# YTM32B1HA0 register map
Vendor: YTMicro; File version: 1.0
CPU: little endian, MPU, FPU, 2 interrupt priority bits
Registers are 32-bit, read-write, reset 0x0 unless marked. A register's access mark holds for its fields unless they carry their own. Offsets are from the block's base; [hi:lo] are bit positions; {n}, {i} and the like mark numbered series; 'fields as' and 'values as' point back to an identical list.

## CAN0 (part 4 of 5) — FlexCAN module
Base 0x400D0000; register names take the prefix CAN0_
0x918 RXIMR38 — The RX Individual Mask Registers are used to store the acceptance masks for ID filtering in Rx MBs and the Legacy Rx FIFO. When the Legacy Rx FIFO is disabled (CAN_MCR.RFEN is negated), an individual mask is provided for each available Rx mailbox on a one-to-one correspondence. When the Legacy Rx FIFO is enabled (CAN_MCR.RFEN is asserted), an individual mask is provided for each Legacy Rx FIFO ID Filter Table Element on a one-to-one correspondence depending on the setting of $ ewline$ CAN_CTRL2.RFFN (see \hyperref[legacy-rx-fifo]{"Legacy Rx FIFO"}). CAN_RXIMR0 stores the individual mask associated with either MB0 or ID Filter Table Element 0, CAN_RXIMR1 stores the individual mask associated with either MB1 or ID Filter Table Element 1, and so on. CAN_RXIMRn registers can only be accessed by the CPU when the FlexCAN is in Freeze mode; otherwise, they are blocked by hardware. The CAN_RXIMRn registers are not affected by reset. They are located in RAM and must be explicitly initialized prior to any reception. The CAN_RXIMRn registers are not available if parameter IRMQ_EN is 0.
  [31:0] MI — Each Individual Mask Bit masks the corresponding bit in both the mailbox filter and Legacy Rx FIFO ID Filter Table element in distinct ways. For mailbox filters, see the RXMGMASK register description. For Legacy Rx FIFO ID Filter Table elements, see the RXFGMASK register description. 0b - The corresponding bit in the filter is ``don't care". 1b - The corresponding bit in the filter is checked.
0x91C RXIMR39 — The RX Individual Mask Registers are used to store the acceptance masks for ID filtering in Rx MBs and the Legacy Rx FIFO. When the Legacy Rx FIFO is disabled (CAN_MCR.RFEN is negated), an individual mask is provided for each available Rx mailbox on a one-to-one correspondence. When the Legacy Rx FIFO is enabled (CAN_MCR.RFEN is asserted), an individual mask is provided for each Legacy Rx FIFO ID Filter Table Element on a one-to-one correspondence depending on the setting of $ ewline$ CAN_CTRL2.RFFN (see \hyperref[legacy-rx-fifo]{"Legacy Rx FIFO"}). CAN_RXIMR0 stores the individual mask associated with either MB0 or ID Filter Table Element 0, CAN_RXIMR1 stores the individual mask associated with either MB1 or ID Filter Table Element 1, and so on. CAN_RXIMRn registers can only be accessed by the CPU when the FlexCAN is in Freeze mode; otherwise, they are blocked by hardware. The CAN_RXIMRn registers are not affected by reset. They are located in RAM and must be explicitly initialized prior to any reception. The CAN_RXIMRn registers are not available if parameter IRMQ_EN is 0.
  fields as RXIMR38
0x920 RXIMR40 — The RX Individual Mask Registers are used to store the acceptance masks for ID filtering in Rx MBs and the Legacy Rx FIFO. When the Legacy Rx FIFO is disabled (CAN_MCR.RFEN is negated), an individual mask is provided for each available Rx mailbox on a one-to-one correspondence. When the Legacy Rx FIFO is enabled (CAN_MCR.RFEN is asserted), an individual mask is provided for each Legacy Rx FIFO ID Filter Table Element on a one-to-one correspondence depending on the setting of $ ewline$ CAN_CTRL2.RFFN (see \hyperref[legacy-rx-fifo]{"Legacy Rx FIFO"}). CAN_RXIMR0 stores the individual mask associated with either MB0 or ID Filter Table Element 0, CAN_RXIMR1 stores the individual mask associated with either MB1 or ID Filter Table Element 1, and so on. CAN_RXIMRn registers can only be accessed by the CPU when the FlexCAN is in Freeze mode; otherwise, they are blocked by hardware. The CAN_RXIMRn registers are not affected by reset. They are located in RAM and must be explicitly initialized prior to any reception. The CAN_RXIMRn registers are not available if parameter IRMQ_EN is 0.
  fields as RXIMR38
0x924 RXIMR41 — The RX Individual Mask Registers are used to store the acceptance masks for ID filtering in Rx MBs and the Legacy Rx FIFO. When the Legacy Rx FIFO is disabled (CAN_MCR.RFEN is negated), an individual mask is provided for each available Rx mailbox on a one-to-one correspondence. When the Legacy Rx FIFO is enabled (CAN_MCR.RFEN is asserted), an individual mask is provided for each Legacy Rx FIFO ID Filter Table Element on a one-to-one correspondence depending on the setting of $ ewline$ CAN_CTRL2.RFFN (see \hyperref[legacy-rx-fifo]{"Legacy Rx FIFO"}). CAN_RXIMR0 stores the individual mask associated with either MB0 or ID Filter Table Element 0, CAN_RXIMR1 stores the individual mask associated with either MB1 or ID Filter Table Element 1, and so on. CAN_RXIMRn registers can only be accessed by the CPU when the FlexCAN is in Freeze mode; otherwise, they are blocked by hardware. The CAN_RXIMRn registers are not affected by reset. They are located in RAM and must be explicitly initialized prior to any reception. The CAN_RXIMRn registers are not available if parameter IRMQ_EN is 0.
  fields as RXIMR38
0x928 RXIMR42 — The RX Individual Mask Registers are used to store the acceptance masks for ID filtering in Rx MBs and the Legacy Rx FIFO. When the Legacy Rx FIFO is disabled (CAN_MCR.RFEN is negated), an individual mask is provided for each available Rx mailbox on a one-to-one correspondence. When the Legacy Rx FIFO is enabled (CAN_MCR.RFEN is asserted), an individual mask is provided for each Legacy Rx FIFO ID Filter Table Element on a one-to-one correspondence depending on the setting of $ ewline$ CAN_CTRL2.RFFN (see \hyperref[legacy-rx-fifo]{"Legacy Rx FIFO"}). CAN_RXIMR0 stores the individual mask associated with either MB0 or ID Filter Table Element 0, CAN_RXIMR1 stores the individual mask associated with either MB1 or ID Filter Table Element 1, and so on. CAN_RXIMRn registers can only be accessed by the CPU when the FlexCAN is in Freeze mode; otherwise, they are blocked by hardware. The CAN_RXIMRn registers are not affected by reset. They are located in RAM and must be explicitly initialized prior to any reception. The CAN_RXIMRn registers are not available if parameter IRMQ_EN is 0.
  fields as RXIMR38
0x92C RXIMR43 — The RX Individual Mask Registers are used to store the acceptance masks for ID filtering in Rx MBs and the Legacy Rx FIFO. When the Legacy Rx FIFO is disabled (CAN_MCR.RFEN is negated), an individual mask is provided for each available Rx mailbox on a one-to-one correspondence. When the Legacy Rx FIFO is enabled (CAN_MCR.RFEN is asserted), an individual mask is provided for each Legacy Rx FIFO ID Filter Table Element on a one-to-one correspondence depending on the setting of $ ewline$ CAN_CTRL2.RFFN (see \hyperref[legacy-rx-fifo]{"Legacy Rx FIFO"}). CAN_RXIMR0 stores the individual mask associated with either MB0 or ID Filter Table Element 0, CAN_RXIMR1 stores the individual mask associated with either MB1 or ID Filter Table Element 1, and so on. CAN_RXIMRn registers can only be accessed by the CPU when the FlexCAN is in Freeze mode; otherwise, they are blocked by hardware. The CAN_RXIMRn registers are not affected by reset. They are located in RAM and must be explicitly initialized prior to any reception. The CAN_RXIMRn registers are not available if parameter IRMQ_EN is 0.
  fields as RXIMR38
0x930 RXIMR44 — The RX Individual Mask Registers are used to store the acceptance masks for ID filtering in Rx MBs and the Legacy Rx FIFO. When the Legacy Rx FIFO is disabled (CAN_MCR.RFEN is negated), an individual mask is provided for each available Rx mailbox on a one-to-one correspondence. When the Legacy Rx FIFO is enabled (CAN_MCR.RFEN is asserted), an individual mask is provided for each Legacy Rx FIFO ID Filter Table Element on a one-to-one correspondence depending on the setting of $ ewline$ CAN_CTRL2.RFFN (see \hyperref[legacy-rx-fifo]{"Legacy Rx FIFO"}). CAN_RXIMR0 stores the individual mask associated with either MB0 or ID Filter Table Element 0, CAN_RXIMR1 stores the individual mask associated with either MB1 or ID Filter Table Element 1, and so on. CAN_RXIMRn registers can only be accessed by the CPU when the FlexCAN is in Freeze mode; otherwise, they are blocked by hardware. The CAN_RXIMRn registers are not affected by reset. They are located in RAM and must be explicitly initialized prior to any reception. The CAN_RXIMRn registers are not available if parameter IRMQ_EN is 0.
  fields as RXIMR38
0x934 RXIMR45 — The RX Individual Mask Registers are used to store the acceptance masks for ID filtering in Rx MBs and the Legacy Rx FIFO. When the Legacy Rx FIFO is disabled (CAN_MCR.RFEN is negated), an individual mask is provided for each available Rx mailbox on a one-to-one correspondence. When the Legacy Rx FIFO is enabled (CAN_MCR.RFEN is asserted), an individual mask is provided for each Legacy Rx FIFO ID Filter Table Element on a one-to-one correspondence depending on the setting of $ ewline$ CAN_CTRL2.RFFN (see \hyperref[legacy-rx-fifo]{"Legacy Rx FIFO"}). CAN_RXIMR0 stores the individual mask associated with either MB0 or ID Filter Table Element 0, CAN_RXIMR1 stores the individual mask associated with either MB1 or ID Filter Table Element 1, and so on. CAN_RXIMRn registers can only be accessed by the CPU when the FlexCAN is in Freeze mode; otherwise, they are blocked by hardware. The CAN_RXIMRn registers are not affected by reset. They are located in RAM and must be explicitly initialized prior to any reception. The CAN_RXIMRn registers are not available if parameter IRMQ_EN is 0.
  fields as RXIMR38
0x938 RXIMR46 — The RX Individual Mask Registers are used to store the acceptance masks for ID filtering in Rx MBs and the Legacy Rx FIFO. When the Legacy Rx FIFO is disabled (CAN_MCR.RFEN is negated), an individual mask is provided for each available Rx mailbox on a one-to-one correspondence. When the Legacy Rx FIFO is enabled (CAN_MCR.RFEN is asserted), an individual mask is provided for each Legacy Rx FIFO ID Filter Table Element on a one-to-one correspondence depending on the setting of $ ewline$ CAN_CTRL2.RFFN (see \hyperref[legacy-rx-fifo]{"Legacy Rx FIFO"}). CAN_RXIMR0 stores the individual mask associated with either MB0 or ID Filter Table Element 0, CAN_RXIMR1 stores the individual mask associated with either MB1 or ID Filter Table Element 1, and so on. CAN_RXIMRn registers can only be accessed by the CPU when the FlexCAN is in Freeze mode; otherwise, they are blocked by hardware. The CAN_RXIMRn registers are not affected by reset. They are located in RAM and must be explicitly initialized prior to any reception. The CAN_RXIMRn registers are not available if parameter IRMQ_EN is 0.
  fields as RXIMR38
0x93C RXIMR47 — The RX Individual Mask Registers are used to store the acceptance masks for ID filtering in Rx MBs and the Legacy Rx FIFO. When the Legacy Rx FIFO is disabled (CAN_MCR.RFEN is negated), an individual mask is provided for each available Rx mailbox on a one-to-one correspondence. When the Legacy Rx FIFO is enabled (CAN_MCR.RFEN is asserted), an individual mask is provided for each Legacy Rx FIFO ID Filter Table Element on a one-to-one correspondence depending on the setting of $ ewline$ CAN_CTRL2.RFFN (see \hyperref[legacy-rx-fifo]{"Legacy Rx FIFO"}). CAN_RXIMR0 stores the individual mask associated with either MB0 or ID Filter Table Element 0, CAN_RXIMR1 stores the individual mask associated with either MB1 or ID Filter Table Element 1, and so on. CAN_RXIMRn registers can only be accessed by the CPU when the FlexCAN is in Freeze mode; otherwise, they are blocked by hardware. The CAN_RXIMRn registers are not affected by reset. They are located in RAM and must be explicitly initialized prior to any reception. The CAN_RXIMRn registers are not available if parameter IRMQ_EN is 0.
  fields as RXIMR38
0x940 RXIMR48 — The RX Individual Mask Registers are used to store the acceptance masks for ID filtering in Rx MBs and the Legacy Rx FIFO. When the Legacy Rx FIFO is disabled (CAN_MCR.RFEN is negated), an individual mask is provided for each available Rx mailbox on a one-to-one correspondence. When the Legacy Rx FIFO is enabled (CAN_MCR.RFEN is asserted), an individual mask is provided for each Legacy Rx FIFO ID Filter Table Element on a one-to-one correspondence depending on the setting of $ ewline$ CAN_CTRL2.RFFN (see \hyperref[legacy-rx-fifo]{"Legacy Rx FIFO"}). CAN_RXIMR0 stores the individual mask associated with either MB0 or ID Filter Table Element 0, CAN_RXIMR1 stores the individual mask associated with either MB1 or ID Filter Table Element 1, and so on. CAN_RXIMRn registers can only be accessed by the CPU when the FlexCAN is in Freeze mode; otherwise, they are blocked by hardware. The CAN_RXIMRn registers are not affected by reset. They are located in RAM and must be explicitly initialized prior to any reception. The CAN_RXIMRn registers are not available if parameter IRMQ_EN is 0.
  fields as RXIMR38
0x944 RXIMR49 — The RX Individual Mask Registers are used to store the acceptance masks for ID filtering in Rx MBs and the Legacy Rx FIFO. When the Legacy Rx FIFO is disabled (CAN_MCR.RFEN is negated), an individual mask is provided for each available Rx mailbox on a one-to-one correspondence. When the Legacy Rx FIFO is enabled (CAN_MCR.RFEN is asserted), an individual mask is provided for each Legacy Rx FIFO ID Filter Table Element on a one-to-one correspondence depending on the setting of $ ewline$ CAN_CTRL2.RFFN (see \hyperref[legacy-rx-fifo]{"Legacy Rx FIFO"}). CAN_RXIMR0 stores the individual mask associated with either MB0 or ID Filter Table Element 0, CAN_RXIMR1 stores the individual mask associated with either MB1 or ID Filter Table Element 1, and so on. CAN_RXIMRn registers can only be accessed by the CPU when the FlexCAN is in Freeze mode; otherwise, they are blocked by hardware. The CAN_RXIMRn registers are not affected by reset. They are located in RAM and must be explicitly initialized prior to any reception. The CAN_RXIMRn registers are not available if parameter IRMQ_EN is 0.
  fields as RXIMR38
0x948 RXIMR50 — The RX Individual Mask Registers are used to store the acceptance masks for ID filtering in Rx MBs and the Legacy Rx FIFO. When the Legacy Rx FIFO is disabled (CAN_MCR.RFEN is negated), an individual mask is provided for each available Rx mailbox on a one-to-one correspondence. When the Legacy Rx FIFO is enabled (CAN_MCR.RFEN is asserted), an individual mask is provided for each Legacy Rx FIFO ID Filter Table Element on a one-to-one correspondence depending on the setting of $ ewline$ CAN_CTRL2.RFFN (see \hyperref[legacy-rx-fifo]{"Legacy Rx FIFO"}). CAN_RXIMR0 stores the individual mask associated with either MB0 or ID Filter Table Element 0, CAN_RXIMR1 stores the individual mask associated with either MB1 or ID Filter Table Element 1, and so on. CAN_RXIMRn registers can only be accessed by the CPU when the FlexCAN is in Freeze mode; otherwise, they are blocked by hardware. The CAN_RXIMRn registers are not affected by reset. They are located in RAM and must be explicitly initialized prior to any reception. The CAN_RXIMRn registers are not available if parameter IRMQ_EN is 0.
  fields as RXIMR38
0x94C RXIMR51 — The RX Individual Mask Registers are used to store the acceptance masks for ID filtering in Rx MBs and the Legacy Rx FIFO. When the Legacy Rx FIFO is disabled (CAN_MCR.RFEN is negated), an individual mask is provided for each available Rx mailbox on a one-to-one correspondence. When the Legacy Rx FIFO is enabled (CAN_MCR.RFEN is asserted), an individual mask is provided for each Legacy Rx FIFO ID Filter Table Element on a one-to-one correspondence depending on the setting of $ ewline$ CAN_CTRL2.RFFN (see \hyperref[legacy-rx-fifo]{"Legacy Rx FIFO"}). CAN_RXIMR0 stores the individual mask associated with either MB0 or ID Filter Table Element 0, CAN_RXIMR1 stores the individual mask associated with either MB1 or ID Filter Table Element 1, and so on. CAN_RXIMRn registers can only be accessed by the CPU when the FlexCAN is in Freeze mode; otherwise, they are blocked by hardware. The CAN_RXIMRn registers are not affected by reset. They are located in RAM and must be explicitly initialized prior to any reception. The CAN_RXIMRn registers are not available if parameter IRMQ_EN is 0.
  fields as RXIMR38
0x950 RXIMR52 — The RX Individual Mask Registers are used to store the acceptance masks for ID filtering in Rx MBs and the Legacy Rx FIFO. When the Legacy Rx FIFO is disabled (CAN_MCR.RFEN is negated), an individual mask is provided for each available Rx mailbox on a one-to-one correspondence. When the Legacy Rx FIFO is enabled (CAN_MCR.RFEN is asserted), an individual mask is provided for each Legacy Rx FIFO ID Filter Table Element on a one-to-one correspondence depending on the setting of $ ewline$ CAN_CTRL2.RFFN (see \hyperref[legacy-rx-fifo]{"Legacy Rx FIFO"}). CAN_RXIMR0 stores the individual mask associated with either MB0 or ID Filter Table Element 0, CAN_RXIMR1 stores the individual mask associated with either MB1 or ID Filter Table Element 1, and so on. CAN_RXIMRn registers can only be accessed by the CPU when the FlexCAN is in Freeze mode; otherwise, they are blocked by hardware. The CAN_RXIMRn registers are not affected by reset. They are located in RAM and must be explicitly initialized prior to any reception. The CAN_RXIMRn registers are not available if parameter IRMQ_EN is 0.
  fields as RXIMR38
0x954 RXIMR53 — The RX Individual Mask Registers are used to store the acceptance masks for ID filtering in Rx MBs and the Legacy Rx FIFO. When the Legacy Rx FIFO is disabled (CAN_MCR.RFEN is negated), an individual mask is provided for each available Rx mailbox on a one-to-one correspondence. When the Legacy Rx FIFO is enabled (CAN_MCR.RFEN is asserted), an individual mask is provided for each Legacy Rx FIFO ID Filter Table Element on a one-to-one correspondence depending on the setting of $ ewline$ CAN_CTRL2.RFFN (see \hyperref[legacy-rx-fifo]{"Legacy Rx FIFO"}). CAN_RXIMR0 stores the individual mask associated with either MB0 or ID Filter Table Element 0, CAN_RXIMR1 stores the individual mask associated with either MB1 or ID Filter Table Element 1, and so on. CAN_RXIMRn registers can only be accessed by the CPU when the FlexCAN is in Freeze mode; otherwise, they are blocked by hardware. The CAN_RXIMRn registers are not affected by reset. They are located in RAM and must be explicitly initialized prior to any reception. The CAN_RXIMRn registers are not available if parameter IRMQ_EN is 0.
  fields as RXIMR38
0x958 RXIMR54 — The RX Individual Mask Registers are used to store the acceptance masks for ID filtering in Rx MBs and the Legacy Rx FIFO. When the Legacy Rx FIFO is disabled (CAN_MCR.RFEN is negated), an individual mask is provided for each available Rx mailbox on a one-to-one correspondence. When the Legacy Rx FIFO is enabled (CAN_MCR.RFEN is asserted), an individual mask is provided for each Legacy Rx FIFO ID Filter Table Element on a one-to-one correspondence depending on the setting of $ ewline$ CAN_CTRL2.RFFN (see \hyperref[legacy-rx-fifo]{"Legacy Rx FIFO"}). CAN_RXIMR0 stores the individual mask associated with either MB0 or ID Filter Table Element 0, CAN_RXIMR1 stores the individual mask associated with either MB1 or ID Filter Table Element 1, and so on. CAN_RXIMRn registers can only be accessed by the CPU when the FlexCAN is in Freeze mode; otherwise, they are blocked by hardware. The CAN_RXIMRn registers are not affected by reset. They are located in RAM and must be explicitly initialized prior to any reception. The CAN_RXIMRn registers are not available if parameter IRMQ_EN is 0.
  fields as RXIMR38
0x95C RXIMR55 — The RX Individual Mask Registers are used to store the acceptance masks for ID filtering in Rx MBs and the Legacy Rx FIFO. When the Legacy Rx FIFO is disabled (CAN_MCR.RFEN is negated), an individual mask is provided for each available Rx mailbox on a one-to-one correspondence. When the Legacy Rx FIFO is enabled (CAN_MCR.RFEN is asserted), an individual mask is provided for each Legacy Rx FIFO ID Filter Table Element on a one-to-one correspondence depending on the setting of $ ewline$ CAN_CTRL2.RFFN (see \hyperref[legacy-rx-fifo]{"Legacy Rx FIFO"}). CAN_RXIMR0 stores the individual mask associated with either MB0 or ID Filter Table Element 0, CAN_RXIMR1 stores the individual mask associated with either MB1 or ID Filter Table Element 1, and so on. CAN_RXIMRn registers can only be accessed by the CPU when the FlexCAN is in Freeze mode; otherwise, they are blocked by hardware. The CAN_RXIMRn registers are not affected by reset. They are located in RAM and must be explicitly initialized prior to any reception. The CAN_RXIMRn registers are not available if parameter IRMQ_EN is 0.
  fields as RXIMR38
0x960 RXIMR56 — The RX Individual Mask Registers are used to store the acceptance masks for ID filtering in Rx MBs and the Legacy Rx FIFO. When the Legacy Rx FIFO is disabled (CAN_MCR.RFEN is negated), an individual mask is provided for each available Rx mailbox on a one-to-one correspondence. When the Legacy Rx FIFO is enabled (CAN_MCR.RFEN is asserted), an individual mask is provided for each Legacy Rx FIFO ID Filter Table Element on a one-to-one correspondence depending on the setting of $ ewline$ CAN_CTRL2.RFFN (see \hyperref[legacy-rx-fifo]{"Legacy Rx FIFO"}). CAN_RXIMR0 stores the individual mask associated with either MB0 or ID Filter Table Element 0, CAN_RXIMR1 stores the individual mask associated with either MB1 or ID Filter Table Element 1, and so on. CAN_RXIMRn registers can only be accessed by the CPU when the FlexCAN is in Freeze mode; otherwise, they are blocked by hardware. The CAN_RXIMRn registers are not affected by reset. They are located in RAM and must be explicitly initialized prior to any reception. The CAN_RXIMRn registers are not available if parameter IRMQ_EN is 0.
  fields as RXIMR38
0x964 RXIMR57 — The RX Individual Mask Registers are used to store the acceptance masks for ID filtering in Rx MBs and the Legacy Rx FIFO. When the Legacy Rx FIFO is disabled (CAN_MCR.RFEN is negated), an individual mask is provided for each available Rx mailbox on a one-to-one correspondence. When the Legacy Rx FIFO is enabled (CAN_MCR.RFEN is asserted), an individual mask is provided for each Legacy Rx FIFO ID Filter Table Element on a one-to-one correspondence depending on the setting of $ ewline$ CAN_CTRL2.RFFN (see \hyperref[legacy-rx-fifo]{"Legacy Rx FIFO"}). CAN_RXIMR0 stores the individual mask associated with either MB0 or ID Filter Table Element 0, CAN_RXIMR1 stores the individual mask associated with either MB1 or ID Filter Table Element 1, and so on. CAN_RXIMRn registers can only be accessed by the CPU when the FlexCAN is in Freeze mode; otherwise, they are blocked by hardware. The CAN_RXIMRn registers are not affected by reset. They are located in RAM and must be explicitly initialized prior to any reception. The CAN_RXIMRn registers are not available if parameter IRMQ_EN is 0.
  fields as RXIMR38
0x968 RXIMR58 — The RX Individual Mask Registers are used to store the acceptance masks for ID filtering in Rx MBs and the Legacy Rx FIFO. When the Legacy Rx FIFO is disabled (CAN_MCR.RFEN is negated), an individual mask is provided for each available Rx mailbox on a one-to-one correspondence. When the Legacy Rx FIFO is enabled (CAN_MCR.RFEN is asserted), an individual mask is provided for each Legacy Rx FIFO ID Filter Table Element on a one-to-one correspondence depending on the setting of $ ewline$ CAN_CTRL2.RFFN (see \hyperref[legacy-rx-fifo]{"Legacy Rx FIFO"}). CAN_RXIMR0 stores the individual mask associated with either MB0 or ID Filter Table Element 0, CAN_RXIMR1 stores the individual mask associated with either MB1 or ID Filter Table Element 1, and so on. CAN_RXIMRn registers can only be accessed by the CPU when the FlexCAN is in Freeze mode; otherwise, they are blocked by hardware. The CAN_RXIMRn registers are not affected by reset. They are located in RAM and must be explicitly initialized prior to any reception. The CAN_RXIMRn registers are not available if parameter IRMQ_EN is 0.
  fields as RXIMR38
0x96C RXIMR59 — The RX Individual Mask Registers are used to store the acceptance masks for ID filtering in Rx MBs and the Legacy Rx FIFO. When the Legacy Rx FIFO is disabled (CAN_MCR.RFEN is negated), an individual mask is provided for each available Rx mailbox on a one-to-one correspondence. When the Legacy Rx FIFO is enabled (CAN_MCR.RFEN is asserted), an individual mask is provided for each Legacy Rx FIFO ID Filter Table Element on a one-to-one correspondence depending on the setting of $ ewline$ CAN_CTRL2.RFFN (see \hyperref[legacy-rx-fifo]{"Legacy Rx FIFO"}). CAN_RXIMR0 stores the individual mask associated with either MB0 or ID Filter Table Element 0, CAN_RXIMR1 stores the individual mask associated with either MB1 or ID Filter Table Element 1, and so on. CAN_RXIMRn registers can only be accessed by the CPU when the FlexCAN is in Freeze mode; otherwise, they are blocked by hardware. The CAN_RXIMRn registers are not affected by reset. They are located in RAM and must be explicitly initialized prior to any reception. The CAN_RXIMRn registers are not available if parameter IRMQ_EN is 0.
  fields as RXIMR38
0x970 RXIMR60 — The RX Individual Mask Registers are used to store the acceptance masks for ID filtering in Rx MBs and the Legacy Rx FIFO. When the Legacy Rx FIFO is disabled (CAN_MCR.RFEN is negated), an individual mask is provided for each available Rx mailbox on a one-to-one correspondence. When the Legacy Rx FIFO is enabled (CAN_MCR.RFEN is asserted), an individual mask is provided for each Legacy Rx FIFO ID Filter Table Element on a one-to-one correspondence depending on the setting of $ ewline$ CAN_CTRL2.RFFN (see \hyperref[legacy-rx-fifo]{"Legacy Rx FIFO"}). CAN_RXIMR0 stores the individual mask associated with either MB0 or ID Filter Table Element 0, CAN_RXIMR1 stores the individual mask associated with either MB1 or ID Filter Table Element 1, and so on. CAN_RXIMRn registers can only be accessed by the CPU when the FlexCAN is in Freeze mode; otherwise, they are blocked by hardware. The CAN_RXIMRn registers are not affected by reset. They are located in RAM and must be explicitly initialized prior to any reception. The CAN_RXIMRn registers are not available if parameter IRMQ_EN is 0.
  fields as RXIMR38
0x974 RXIMR61 — The RX Individual Mask Registers are used to store the acceptance masks for ID filtering in Rx MBs and the Legacy Rx FIFO. When the Legacy Rx FIFO is disabled (CAN_MCR.RFEN is negated), an individual mask is provided for each available Rx mailbox on a one-to-one correspondence. When the Legacy Rx FIFO is enabled (CAN_MCR.RFEN is asserted), an individual mask is provided for each Legacy Rx FIFO ID Filter Table Element on a one-to-one correspondence depending on the setting of $ ewline$ CAN_CTRL2.RFFN (see \hyperref[legacy-rx-fifo]{"Legacy Rx FIFO"}). CAN_RXIMR0 stores the individual mask associated with either MB0 or ID Filter Table Element 0, CAN_RXIMR1 stores the individual mask associated with either MB1 or ID Filter Table Element 1, and so on. CAN_RXIMRn registers can only be accessed by the CPU when the FlexCAN is in Freeze mode; otherwise, they are blocked by hardware. The CAN_RXIMRn registers are not affected by reset. They are located in RAM and must be explicitly initialized prior to any reception. The CAN_RXIMRn registers are not available if parameter IRMQ_EN is 0.
  fields as RXIMR38
0x978 RXIMR62 — The RX Individual Mask Registers are used to store the acceptance masks for ID filtering in Rx MBs and the Legacy Rx FIFO. When the Legacy Rx FIFO is disabled (CAN_MCR.RFEN is negated), an individual mask is provided for each available Rx mailbox on a one-to-one correspondence. When the Legacy Rx FIFO is enabled (CAN_MCR.RFEN is asserted), an individual mask is provided for each Legacy Rx FIFO ID Filter Table Element on a one-to-one correspondence depending on the setting of $ ewline$ CAN_CTRL2.RFFN (see \hyperref[legacy-rx-fifo]{"Legacy Rx FIFO"}). CAN_RXIMR0 stores the individual mask associated with either MB0 or ID Filter Table Element 0, CAN_RXIMR1 stores the individual mask associated with either MB1 or ID Filter Table Element 1, and so on. CAN_RXIMRn registers can only be accessed by the CPU when the FlexCAN is in Freeze mode; otherwise, they are blocked by hardware. The CAN_RXIMRn registers are not affected by reset. They are located in RAM and must be explicitly initialized prior to any reception. The CAN_RXIMRn registers are not available if parameter IRMQ_EN is 0.
  fields as RXIMR38
0x97C RXIMR63 — The RX Individual Mask Registers are used to store the acceptance masks for ID filtering in Rx MBs and the Legacy Rx FIFO. When the Legacy Rx FIFO is disabled (CAN_MCR.RFEN is negated), an individual mask is provided for each available Rx mailbox on a one-to-one correspondence. When the Legacy Rx FIFO is enabled (CAN_MCR.RFEN is asserted), an individual mask is provided for each Legacy Rx FIFO ID Filter Table Element on a one-to-one correspondence depending on the setting of $ ewline$ CAN_CTRL2.RFFN (see \hyperref[legacy-rx-fifo]{"Legacy Rx FIFO"}). CAN_RXIMR0 stores the individual mask associated with either MB0 or ID Filter Table Element 0, CAN_RXIMR1 stores the individual mask associated with either MB1 or ID Filter Table Element 1, and so on. CAN_RXIMRn registers can only be accessed by the CPU when the FlexCAN is in Freeze mode; otherwise, they are blocked by hardware. The CAN_RXIMRn registers are not affected by reset. They are located in RAM and must be explicitly initialized prior to any reception. The CAN_RXIMRn registers are not available if parameter IRMQ_EN is 0.
  fields as RXIMR38
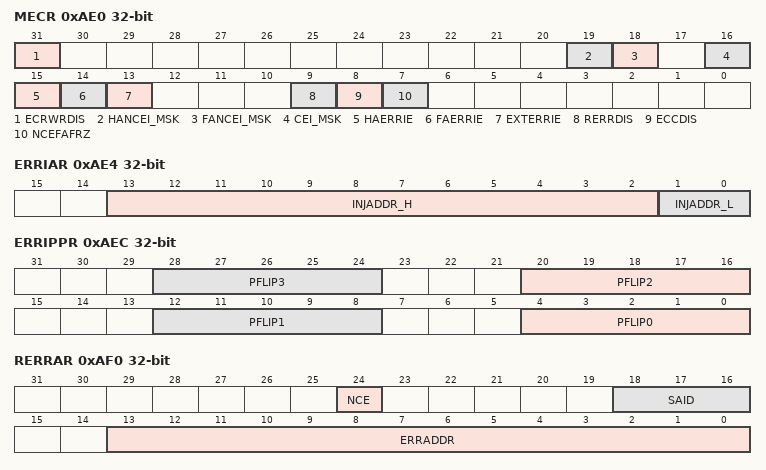
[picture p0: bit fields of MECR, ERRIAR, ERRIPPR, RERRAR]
0xAE0 MECR — The CAN_MECR register contains control bits for memory error detection and correction (ECC). NOTE: When CAN_CTRL2.ECRWRE is 0, writes to CAN_MECR are blocked, with the exception of the ECRWRDIS bit.
  [31] ECRWRDIS — ECRWRDIS is automatically set to 1 (disabled) when CTRL2.ECRWRE is asserted. The protocol described in \hyperref[detection-and-correction-of-memory-errors]{"Detection and Correction of Memory Errors"} must be followed.
    0=Write is enabled; 1=Write is disabled
  [19] HANCEI_MSK — Enables the interrupt in case of non-correctable errors detected in memory reads issued by the host (CPU).
    0=Interrupt is disabled; 1=Interrupt is enabled
  [18] FANCEI_MSK — Enables the interrupt in case of non-correctable errors detected in memory reads issued by the FlexCAN internal processes.
    0=Interrupt is disabled; 1=Interrupt is enabled
  [16] CEI_MSK — Enables the interrupt in case of correctable errors detected in memory reads issued by the host or FlexCAN internal processes.
    0=Interrupt is disabled; 1=Interrupt is enabled
  [15] HAERRIE — Enables the injection of errors only in memory reads issued by the host (CPU).
    0=Interrupt is disabled; 1=Interrupt is enabled
  [14] FAERRIE — Enables the injection of errors only in memory reads issued by the FlexCAN internal processes.
    0=Interrupt is disabled; 1=Interrupt is enabled
  [13] EXTERRIE — Memory accesses performed by internal FlexCAN processes are 64-bit accesses. EXTERRIE extends the error injection on 32-bit memory accesses to the complementary 32-bit word using the same 32-bit error injection data and parity words. See 'Error Injection Data Pattern Register (CAN_ERRIDPR)' and 'Error Injection Parity Pattern Register (CAN_ERRIPPR)'.
    0=Error injection is applied only to the 32-bit word; 1=Error injection is applied to the 64-bit word
  [9] RERRDIS — NOTE: When reading the report registers, RERRDIS must be set to ensure coherence on the consecutive register reads.
    0=Enable updates of the error report registers; 1=Disable updates of the error report registers. The update of error-related flags and the generation of bus transfer errors are still active.
  [8] ECCDIS — In addition to disabling the error report mechanism, ECCDIS = 1 also stops the update of the error-related flags and generation of bus transfer errors. The parity bits continue to be calculated and written into memory on write transactions.
    0=Enable memory error correction; 1=Disable memory error correction
  [7] NCEFAFRZ — Determines the response when a non-correctable error is detected in a memory read performed by FlexCAN internal processes.
    0=Keep normal operation; 1=Put FlexCAN in Freeze mode (according to \hyperref[freeze-mode]{"Freeze Mode"}). In this case, entering Freeze mode prevents corrupted data from being treated as valid by FlexCAN internal processes.
0xAE4 ERRIAR
  [13:2] INJADDR_H — Defines the twelve most significant bits of the physical RAM address where a memory read error is to be injected. See \hyperref[CAN-error-injection-address-mapping-for-maximum-configuration]{CAN error injection address mapping for maximum configuration}
  [1:0] INJADDR_L — Read-only field that defines the two least significant bits of the physical RAM address where a memory read error is to be injected. INJADDR_L[1:0] are always zero to ensure that the address is on a 32-bit boundary.
0xAE8 ERRIDPR — The CAN_ERRIDPR register holds the error pattern to be injected in the data word read from memory. The CAN_ERRIDPR register is not available when parameter ECC_EN is 0.
  [31:0] DFLIP — Bits set to 1 in the flip pattern cause the corresponding data bit in the word read from memory to invert.
0xAEC ERRIPPR — The CAN_ERRIPPR register holds the error pattern to be injected in parity bits read from memory along with data word. Bits set to 1 in the flip pattern cause the corresponding parity bit in the word read from memory to invert. The CAN_ERRIPPR register is not available when parameter ECC_EN is 0.
  [8n+4:8n] PFLIP{n} (n=0..3)
0xAF0 RERRAR — The CAN_RERRAR register reports the address used for an access in which an error (correctable or non-correctable) was detected, and reports the identification of the source of that access. The address is always reported using a 32-bit alignment. Non-aligned accesses ewline (CAN_ERRADDR[1:0] are non-0) are reported with the address aligned and data is reported in CAN_RERRDR accordingly shifted. In case of errors detected in accesses larger than 32-bit (as performed by FlexCAN internal processes), the address of the 32-bit word in which the error was detected is reported. In case of errors detected in more than one 32-bit word, only the least significant address is reported. The CAN_RERRAR register is not available when parameter ECC_EN is 0.
  [24] NCE ro — Indicates that the report is due to a noncorrectable error.
    0=Reporting a correctable-error; 1=Reporting a non-correctable error
  [18:16] SAID ro — SAID[2] - Identification of the requestor of the memory read request: • 0: Requested by FlexCAN internal processes • 1: Requested by host (CPU) SAID[1] - Details of FlexCAN operation: • 0: Move • 1: Scanning SAID[0] - Operation that requested the memory read: • 0: Transmission • 1: Reception
  [13:0] ERRADDR ro

## CAN1 (part 4 of 5) — FlexCAN module
Base 0x400D4000; register names take the prefix CAN1_
Registers as CAN0.

## CAN2 (part 4 of 5) — FlexCAN module
Base 0x400D8000; register names take the prefix CAN2_
Registers as CAN0.

## CAN3 (part 4 of 5) — FlexCAN module
Base 0x400DC000; register names take the prefix CAN3_
Registers as CAN0.

## CAN4 (part 4 of 5) — FlexCAN module
Base 0x400E0000; register names take the prefix CAN4_
Registers as CAN0.

## CAN5 (part 4 of 5) — FlexCAN module
Base 0x400E4000; register names take the prefix CAN5_
Registers as CAN0.

## CAN6 (part 4 of 5) — FlexCAN module
Base 0x400E8000; register names take the prefix CAN6_
Registers as CAN0.

## CAN7 (part 4 of 5) — FlexCAN module
Base 0x400EC000; register names take the prefix CAN7_
Registers as CAN0.
